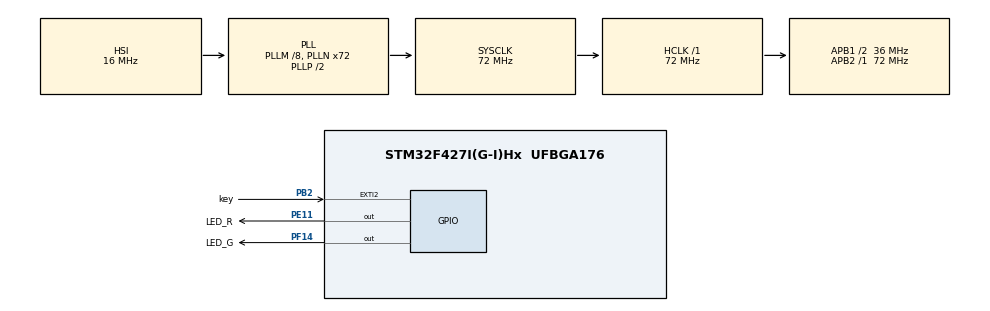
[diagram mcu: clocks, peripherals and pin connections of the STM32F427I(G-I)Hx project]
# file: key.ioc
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Mcu.Family=STM32F4
Mcu.Name=STM32F427I(G-I)Hx
Mcu.Package=UFBGA176
NVIC.EXTI2_IRQn=true\:2\:0\:true\:false\:true\:true\:true\:true
NVIC.PriorityGroup=NVIC_PRIORITYGROUP_4
PB2/BOOT1.GPIO_Label=key
PB2/BOOT1.GPIO_ModeDefaultEXTI=GPIO_MODE_IT_RISING
PB2/BOOT1.GPIO_PuPd=GPIO_PULLDOWN
PB2/BOOT1.Signal=GPXTI2
PC14/OSC32_IN.Mode=LSE-External-Oscillator
PC14/OSC32_IN.Signal=RCC_OSC32_IN
PC15/OSC32_OUT.Mode=LSE-External-Oscillator
PC15/OSC32_OUT.Signal=RCC_OSC32_OUT
PE11.GPIO_Label=LED_R
PE11.GPIO_PuPd=GPIO_PULLUP
PE11.GPIO_Speed=GPIO_SPEED_FREQ_MEDIUM
PE11.PinState=GPIO_PIN_SET
PE11.Signal=GPIO_Output
PF14.GPIO_Label=LED_G
PF14.GPIO_PuPd=GPIO_PULLUP
PF14.GPIO_Speed=GPIO_SPEED_FREQ_MEDIUM
PF14.PinState=GPIO_PIN_SET
PF14.Signal=GPIO_Output
PH0/OSC_IN.Mode=HSE-External-Oscillator
PH0/OSC_IN.Signal=RCC_OSC_IN
PH1/OSC_OUT.Mode=HSE-External-Oscillator
PH1/OSC_OUT.Signal=RCC_OSC_OUT
ProjectManager.HeapSize=0x200
ProjectManager.StackSize=0x400
ProjectManager.TargetToolchain=MDK-ARM V5.32
RCC.48MHZClocksFreq_Value=36000000
RCC.AHBFreq_Value=72000000
RCC.APB1CLKDivider=RCC_HCLK_DIV2
RCC.APB1Freq_Value=36000000
RCC.APB1TimFreq_Value=72000000
RCC.APB2Freq_Value=72000000
RCC.APB2TimFreq_Value=72000000
RCC.CortexFreq_Value=72000000
RCC.HCLKFreq_Value=72000000
RCC.HSE_VALUE=25000000
RCC.HSI_VALUE=16000000
RCC.PLLM=8
RCC.PLLN=72
RCC.SYSCLKFreq_VALUE=72000000
RCC.SYSCLKSource=RCC_SYSCLKSOURCE_PLLCLK
RCC.VCOOutputFreq_Value=144000000
board=custom

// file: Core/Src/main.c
/* USER CODE BEGIN Header */
/**
  ******************************************************************************
  * @file           : main.c
  * @brief          : Main program body
  ******************************************************************************
  * @attention
  *
  * Copyright (c) 2023 STMicroelectronics.
  * All rights reserved.
  *
  * This software is licensed under terms that can be found in the LICENSE file
  * in the root directory of this software component.
  * If no LICENSE file comes with this software, it is provided AS-IS.
  *
  ******************************************************************************
  */
/* USER CODE END Header */
#include "main.h"
#include "gpio.h"

void SystemClock_Config(void);

int main(void)
{

  /* MCU Configuration--------------------------------------------------------*/

  /* Reset of all peripherals, Initializes the Flash interface and the Systick. */
  HAL_Init();

  /* Configure the system clock */
  SystemClock_Config();

  /* Initialize all configured peripherals */
  MX_GPIO_Init();

  /* Infinite loop */
  while (1)
  {

  }
}

void SystemClock_Config(void)
{
  RCC_OscInitTypeDef RCC_OscInitStruct = {0};
  RCC_ClkInitTypeDef RCC_ClkInitStruct = {0};

  /** Configure the main internal regulator output voltage
  */
  __HAL_RCC_PWR_CLK_ENABLE();
  __HAL_PWR_VOLTAGESCALING_CONFIG(PWR_REGULATOR_VOLTAGE_SCALE3);

  /** Initializes the RCC Oscillators according to the specified parameters
  * in the RCC_OscInitTypeDef structure.
  */
  RCC_OscInitStruct.OscillatorType = RCC_OSCILLATORTYPE_HSI;
  RCC_OscInitStruct.HSIState = RCC_HSI_ON;
  RCC_OscInitStruct.HSICalibrationValue = RCC_HSICALIBRATION_DEFAULT;
  RCC_OscInitStruct.PLL.PLLState = RCC_PLL_ON;
  RCC_OscInitStruct.PLL.PLLSource = RCC_PLLSOURCE_HSI;
  RCC_OscInitStruct.PLL.PLLM = 8;
  RCC_OscInitStruct.PLL.PLLN = 72;
  RCC_OscInitStruct.PLL.PLLP = RCC_PLLP_DIV2;
  RCC_OscInitStruct.PLL.PLLQ = 4;
  if (HAL_RCC_OscConfig(&RCC_OscInitStruct) != HAL_OK)
  {
    Error_Handler();
  }

  /** Initializes the CPU, AHB and APB buses clocks
  */
  RCC_ClkInitStruct.ClockType = RCC_CLOCKTYPE_HCLK|RCC_CLOCKTYPE_SYSCLK
                              |RCC_CLOCKTYPE_PCLK1|RCC_CLOCKTYPE_PCLK2;
  RCC_ClkInitStruct.SYSCLKSource = RCC_SYSCLKSOURCE_PLLCLK;
  RCC_ClkInitStruct.AHBCLKDivider = RCC_SYSCLK_DIV1;
  RCC_ClkInitStruct.APB1CLKDivider = RCC_HCLK_DIV2;
  RCC_ClkInitStruct.APB2CLKDivider = RCC_HCLK_DIV1;

  if (HAL_RCC_ClockConfig(&RCC_ClkInitStruct, FLASH_LATENCY_2) != HAL_OK)
  {
    Error_Handler();
  }
}

/* USER CODE BEGIN 4 */
	void HAL_GPIO_EXTI_Callback(uint16_t GPIO_Pin)
{
		while(1){
			if(HAL_GPIO_ReadPin(GPIOB,GPIO_PIN_2)==0){
				HAL_GPIO_WritePin(GPIOE,GPIO_PIN_11,GPIO_PIN_RESET);
				HAL_GPIO_WritePin(GPIOF,GPIO_PIN_14,GPIO_PIN_SET);
			}
			else{
				HAL_GPIO_WritePin(GPIOE,GPIO_PIN_11,GPIO_PIN_SET);
				HAL_GPIO_WritePin(GPIOF,GPIO_PIN_14,GPIO_PIN_RESET);
			}
		}
}
/* USER CODE END 4 */

void Error_Handler(void)
{
  __disable_irq();
  while (1)
  {
  }
}
